# fcr_me12 register map
Registers are read-write, no defined reset value unless marked. A register's access mark holds for its fields unless they carry their own. Offsets are from the block's base; lines under a group give offsets from that group; [hi:lo] are bit positions; {n}, {i} and the like mark numbered series; 'fields as' and 'values as' point back to an identical list; <NAME> marks a mode.

## Memory map
0x40000800 FCR size 0x400 — Function Control Register.

## FCR — Function Control Register.
Base 0x40000800
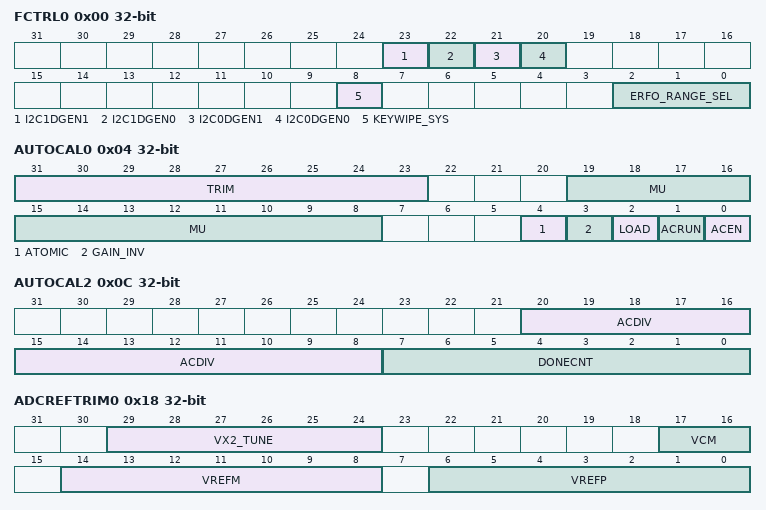
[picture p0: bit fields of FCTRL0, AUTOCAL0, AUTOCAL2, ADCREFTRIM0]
0x00 FCTRL0 — Function Control 0.
  [23] I2C1DGEN1 — I2C1 SCL Pad Deglitcher enable.
    0=dis (Deglitcher disabled.); 1=en (Deglitcher enabled.)
  [22] I2C1DGEN0 — I2C1 SDA Pad Deglitcher enable.
    0=dis (Deglitcher disabled.); 1=en (Deglitcher enabled.)
  [21] I2C0DGEN1 — I2C0 SCL Pad Deglitcher enable.
    0=dis (Deglitcher disabled.); 1=en (Deglitcher enabled.)
  [20] I2C0DGEN0 — I2C0 SDA Pad Deglitcher enable.
    0=dis (Deglitcher disabled.); 1=en (Deglitcher enabled.)
  [8] KEYWIPE_SYS — Wipe System AES Key Register.
  [2:0] ERFO_RANGE_SEL — ERFO Frequency Range Select. Control ibias_gm_stage.
0x04 AUTOCAL0 — Automatic Calibration 0.
  [31:23] TRIM — HIRC96M Trim Value determinged by Auto Calibration.
  [19:8] MU — Adaptation Gain Value.
  [4] ATOMIC — Start atomic autocal.
    0=not (Not Running.); 1=run (Running.)
  [3] GAIN_INV — Invert Gain.
    0=not (Not inverted.); 1=Inverted
  [2] LOAD — Load Trim.
  [1] ACRUN — Autocalibration Run.
    0=not (Not Running.); 1=run (Running.)
  [0] ACEN — Auto-calibration Enable for HIRC96M.
    0=dis (Disabled.); 1=en (Enabled.)
0x08 AUTOCAL1 — Automatic Calibration 1.
  [8:0] INITTRIM — Initial Trim Setting fir HIRC96M Auto Calibration procedure.
0x0C AUTOCAL2 — Automatic Calibration 2
  [20:8] ACDIV — Auto-callibration Divide Factor.
  [7:0] DONECNT — Auto-callibration Done Counter Setting.
0x18 ADCREFTRIM0 — ADC Reference Trim 0 Control Register.
  [29:24] VX2_TUNE — COntrols tuning capacitor in fine DAC, offset binary.
  [17:16] VCM — Trimming code for VCM output of reference buffer.
  [14:8] VREFM — Trimming code for VREFM output of reference buffer.
  [6:0] VREFP — Trimming code for VREFP output of reference buffer.
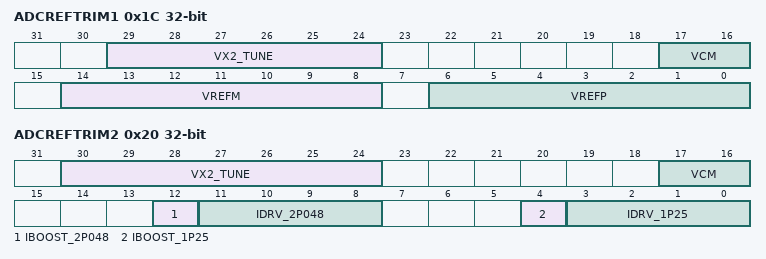
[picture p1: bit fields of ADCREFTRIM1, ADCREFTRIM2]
0x1C ADCREFTRIM1 — ADC Reference Trim 1 Control Register.
  fields as ADCREFTRIM0
0x20 ADCREFTRIM2 — ADC Reference Trim 2 Control Register.
  [30:24] VX2_TUNE — Controls tuning capacitor in fine DAC, offset binary.
  [17:16] VCM — Trimming code for VCM output of reference buffer.
  [12] IBOOST_2P048 — Trimming value for extra drive current in reference buffer outputs, 2.048V Reference.
  [11:8] IDRV_2P048 — Trimming code for reference buffer drive strength, 2.048V Reference.
  [4] IBOOST_1P25 — Trimming value for extra drive current in reference buffer outputsm 1.25V Reference.
  [3:0] IDRV_1P25 — Trimming code for reference buffer drive strength, 1.25V Reference.
0x24 ERFOKS — ERFO Kick Start Control Register.
  [15:0] CTRL — Kickstart Control for ERFO (XO32M)
